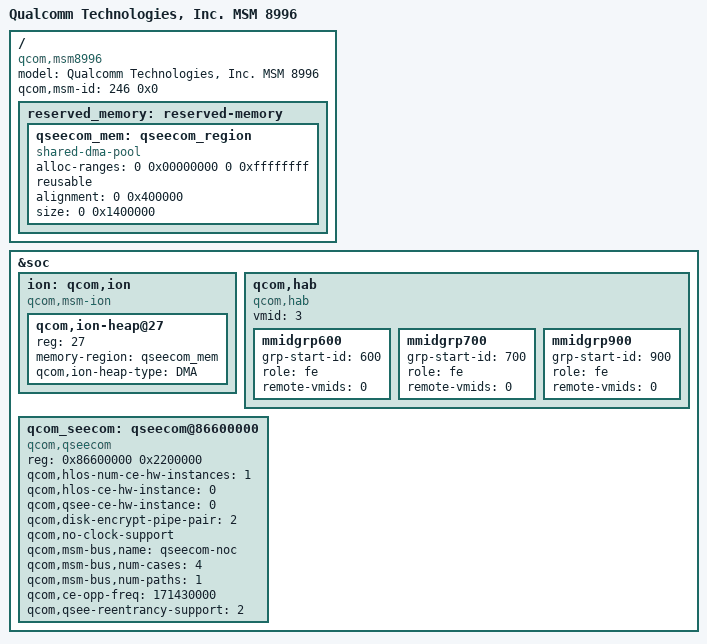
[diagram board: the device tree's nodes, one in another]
/* Copyright (c) 2018, The Linux Foundation. All rights reserved.
 *
 * This program is free software; you can redistribute it and/or modify
 * it under the terms of the GNU General Public License version 2 and
 * only version 2 as published by the Free Software Foundation.
 *
 * This program is distributed in the hope that it will be useful,
 * but WITHOUT ANY WARRANTY; without even the implied warranty of
 * MERCHANTABILITY or FITNESS FOR A PARTICULAR PURPOSE.  See the
 * GNU General Public License for more details.
 */

/dts-v1/;

#include "skeleton64.dtsi"
#include "vplatform-lfv-msm8996-common.dtsi"

/ {
	model = "Qualcomm Technologies, Inc. MSM 8996";
	compatible = "qcom,msm8996";
	qcom,msm-id = <246 0x0>;

	reserved_memory: reserved-memory {
		#address-cells = <2>;
		#size-cells = <2>;
		ranges;

		qseecom_mem: qseecom_region {
			compatible = "shared-dma-pool";
			alloc-ranges = <0 0x00000000 0 0xffffffff>;
			reusable;
			alignment = <0 0x400000>;
			size = <0 0x1400000>;
		};
	};

};

&soc {
	ion: qcom,ion {
		compatible = "qcom,msm-ion";
		#address-cells = <1>;
		#size-cells = <0>;

		qcom,ion-heap@27 { /* QSEECOM HEAP */
			reg = <27>;
			memory-region = <&qseecom_mem>;
			qcom,ion-heap-type = "DMA";
		};
	};
};

&soc {
	qcom,hab {
		compatible = "qcom,hab";
		vmid = <3>;

		mmidgrp600: mmidgrp600 {
			grp-start-id = <600>;
			role = "fe";
			remote-vmids = <0>;
		};

		mmidgrp700: mmidgrp700 {
			grp-start-id = <700>;
			role = "fe";
			remote-vmids = <0>;
		};

		mmidgrp900: mmidgrp900 {
			grp-start-id = <900>;
			role = "fe";
			remote-vmids = <0>;
		};
	};
	qcom_seecom: qseecom@86600000 {
		compatible = "qcom,qseecom";
		reg = <0x86600000 0x2200000>;
		reg-names = "secapp-region";
		qcom,hlos-num-ce-hw-instances = <1>;
		qcom,hlos-ce-hw-instance = <0>;
		qcom,qsee-ce-hw-instance = <0>;
		qcom,disk-encrypt-pipe-pair = <2>;
		qcom,no-clock-support;
		qcom,msm-bus,name = "qseecom-noc";
		qcom,msm-bus,num-cases = <4>;
		qcom,msm-bus,num-paths = <1>;
		qcom,ce-opp-freq = <171430000>;
		qcom,qsee-reentrancy-support = <2>;
	};
};
